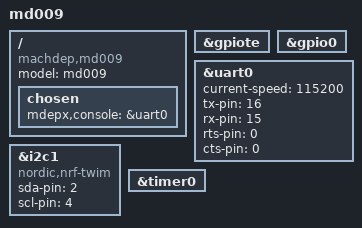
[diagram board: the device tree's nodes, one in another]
/*-
 * Copyright (c) 2020 Ruslan Bukin <br@bsdpad.com>
 * All rights reserved.
 *
 * Redistribution and use in source and binary forms, with or without
 * modification, are permitted provided that the following conditions
 * are met:
 * 1. Redistributions of source code must retain the above copyright
 *    notice, this list of conditions and the following disclaimer.
 * 2. Redistributions in binary form must reproduce the above copyright
 *    notice, this list of conditions and the following disclaimer in the
 *    documentation and/or other materials provided with the distribution.
 *
 * THIS SOFTWARE IS PROVIDED BY THE AUTHOR AND CONTRIBUTORS ``AS IS'' AND
 * ANY EXPRESS OR IMPLIED WARRANTIES, INCLUDING, BUT NOT LIMITED TO, THE
 * IMPLIED WARRANTIES OF MERCHANTABILITY AND FITNESS FOR A PARTICULAR PURPOSE
 * ARE DISCLAIMED.  IN NO EVENT SHALL THE AUTHOR OR CONTRIBUTORS BE LIABLE
 * FOR ANY DIRECT, INDIRECT, INCIDENTAL, SPECIAL, EXEMPLARY, OR CONSEQUENTIAL
 * DAMAGES (INCLUDING, BUT NOT LIMITED TO, PROCUREMENT OF SUBSTITUTE GOODS
 * OR SERVICES; LOSS OF USE, DATA, OR PROFITS; OR BUSINESS INTERRUPTION)
 * HOWEVER CAUSED AND ON ANY THEORY OF LIABILITY, WHETHER IN CONTRACT, STRICT
 * LIABILITY, OR TORT (INCLUDING NEGLIGENCE OR OTHERWISE) ARISING IN ANY WAY
 * OUT OF THE USE OF THIS SOFTWARE, EVEN IF ADVISED OF THE POSSIBILITY OF
 * SUCH DAMAGE.
 */

/dts-v1/;

#include <nordic/nrf9160ns_sica.dtsi>

/ {
	model = "md009";
	compatible = "machdep,md009";

	chosen {
		mdepx,console = &uart0;
	};
};

&gpiote {
	status = "okay";
};

&gpio0 {
	status = "okay";
};

&uart0 {
	status = "okay";
	current-speed = <115200>;
	tx-pin = <16>;
	rx-pin = <15>;
	rts-pin = <0>;
	cts-pin = <0>;
};

&i2c1 {
	compatible = "nordic,nrf-twim";
	status = "okay";
	sda-pin = <2>;
	scl-pin = <4>;
};

&timer0 {
	status = "okay";
};
